# STM32F101C4T6 register map
File version: 1.0
Registers are 32-bit, access not given, reset 0x0 unless marked. A register's access mark holds for its fields unless they carry their own. Offsets are from the block's base; [hi:lo] are bit positions.

## TIM6
Base 0x40001000
Same registers: TIM7 0x40001400
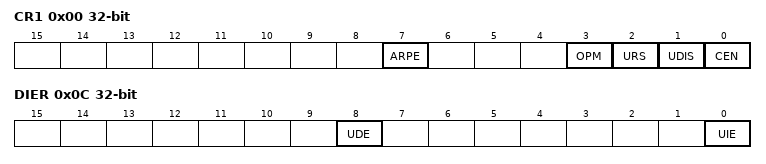
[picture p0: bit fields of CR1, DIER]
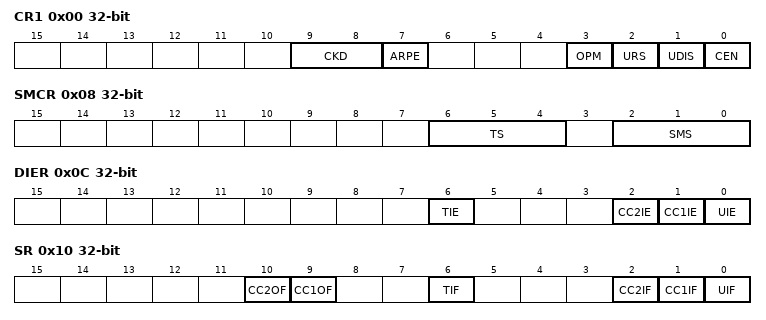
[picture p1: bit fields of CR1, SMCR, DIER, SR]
0x00 CR1
  [7] ARPE, [3] OPM, [2] URS, [1] UDIS, [0] CEN
0x04 CR2
  [6:4] MMS
0x0C DIER
  [8] UDE, [0] UIE
0x10 SR
  [0] UIF
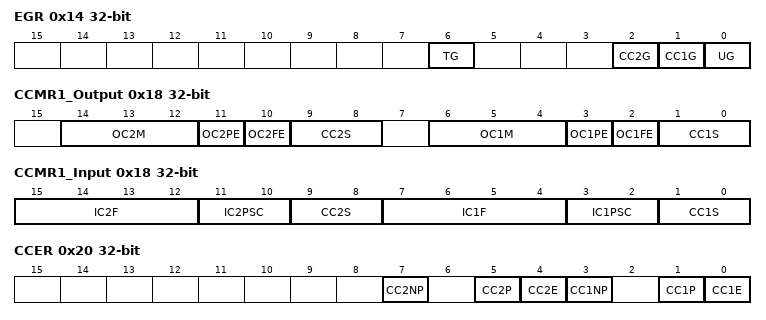
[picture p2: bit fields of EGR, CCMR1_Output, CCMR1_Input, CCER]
0x14 EGR
  [0] UG
0x24 CNT
  [15:0] CNT
0x28 PSC
  [15:0] PSC
0x2C ARR
  [15:0] ARR

## TIM12
Base 0x40001800
Same registers: TIM9 0x40014C00
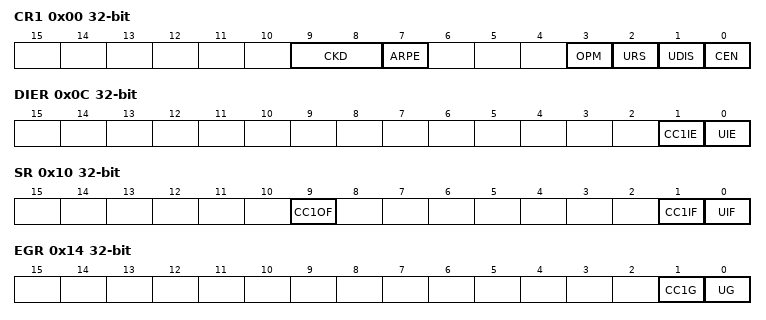
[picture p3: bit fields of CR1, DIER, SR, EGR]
0x00 CR1
  [9:8] CKD, [7] ARPE, [3] OPM, [2] URS, [1] UDIS, [0] CEN
0x08 SMCR
  [6:4] TS, [2:0] SMS
0x0C DIER
  [6] TIE, [2] CC2IE, [1] CC1IE, [0] UIE
0x10 SR
  [10] CC2OF, [9] CC1OF, [6] TIF, [2] CC2IF, [1] CC1IF, [0] UIF
0x14 EGR
  [6] TG, [2] CC2G, [1] CC1G, [0] UG
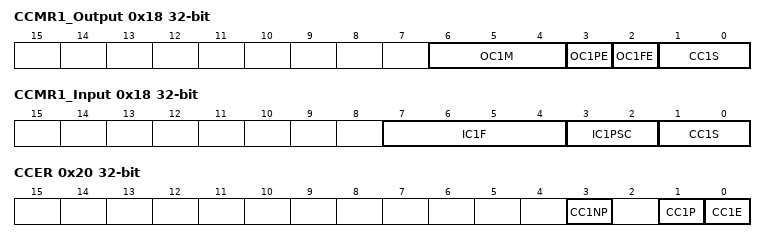
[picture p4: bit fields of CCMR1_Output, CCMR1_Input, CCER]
0x18 CCMR1_Output
  [14:12] OC2M, [11] OC2PE, [10] OC2FE, [9:8] CC2S, [6:4] OC1M, [3] OC1PE, [2] OC1FE, [1:0] CC1S
0x18 CCMR1_Input
  [15:12] IC2F, [11:10] IC2PSC, [9:8] CC2S, [7:4] IC1F, [3:2] IC1PSC, [1:0] CC1S
0x20 CCER
  [7] CC2NP, [5] CC2P, [4] CC2E, [3] CC1NP, [1] CC1P, [0] CC1E
0x24 CNT
  [15:0] CNT
0x28 PSC
  [15:0] PSC
0x2C ARR
  [15:0] ARR
0x34 CCR1
  [15:0] CCR1
0x38 CCR2
  [15:0] CCR2

## TIM13
Base 0x40001C00
Same registers: TIM14 0x40002000, TIM10 0x40015000, TIM11 0x40015400
0x00 CR1
  [9:8] CKD, [7] ARPE, [3] OPM, [2] URS, [1] UDIS, [0] CEN
0x08 SMCR
0x0C DIER
  [1] CC1IE, [0] UIE
0x10 SR
  [9] CC1OF, [1] CC1IF, [0] UIF
0x14 EGR
  [1] CC1G, [0] UG
0x18 CCMR1_Output
  [6:4] OC1M, [3] OC1PE, [2] OC1FE, [1:0] CC1S
0x18 CCMR1_Input
  [7:4] IC1F, [3:2] IC1PSC, [1:0] CC1S
0x20 CCER
  [3] CC1NP, [1] CC1P, [0] CC1E
0x24 CNT
  [15:0] CNT
0x28 PSC
  [15:0] PSC
0x2C ARR
  [15:0] ARR
0x34 CCR1
  [15:0] CCR1

## RTC
Base 0x40002800
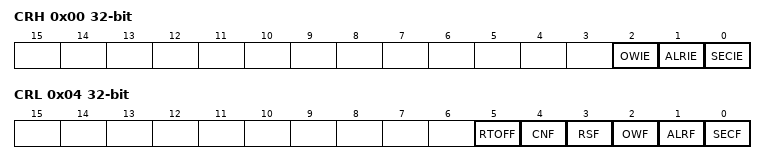
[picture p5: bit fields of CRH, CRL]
0x00 CRH
  [2] OWIE, [1] ALRIE, [0] SECIE
0x04 CRL
  [5] RTOFF, [4] CNF, [3] RSF, [2] OWF, [1] ALRF, [0] SECF
0x08 PRLH
  [3:0] PRL
0x0C PRLL
  [15:0] PRL
0x10 DIVH
  [15:0] DIV
0x14 DIVL
  [15:0] DIV
0x18 CNTH
  [15:0] CNT
0x1C CNTL
  [15:0] CNT
0x20 ALRH
  [15:0] ALR
0x24 ALRL
  [15:0] ALR

## WWDG
Base 0x40002C00
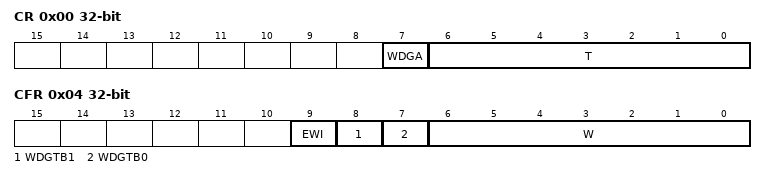
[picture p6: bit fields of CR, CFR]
0x00 CR
  [7] WDGA, [6:0] T
0x04 CFR
  [9] EWI, [8] WDGTB1, [7] WDGTB0, [6:0] W
0x08 SR
  [0] EWIF

## IWDG
Base 0x40003000
0x00 KR
  [15:0] KEY
0x04 PR
  [2:0] PR
0x08 RLR
  [11:0] RL
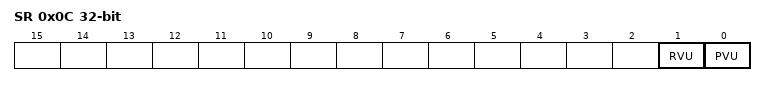
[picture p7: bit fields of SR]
0x0C SR
  [1] RVU, [0] PVU

## SPI2
Base 0x40003800
Same registers: SPI3 0x40003C00, SPI1 0x40013000
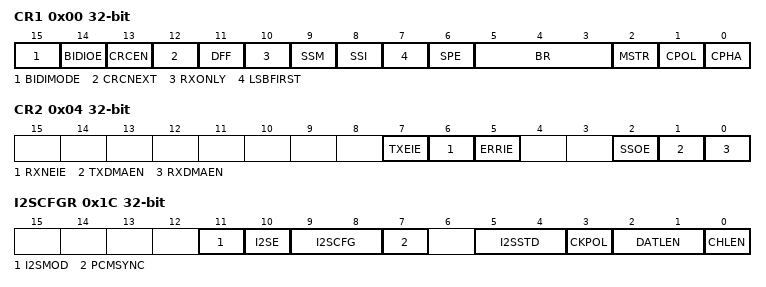
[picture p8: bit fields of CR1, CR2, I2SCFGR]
0x00 CR1
  [15] BIDIMODE, [14] BIDIOE, [13] CRCEN, [12] CRCNEXT, [11] DFF, [10] RXONLY, [9] SSM, [8] SSI, [7] LSBFIRST, [6] SPE, [5:3] BR, [2] MSTR, [1] CPOL, [0] CPHA
0x04 CR2
  [7] TXEIE, [6] RXNEIE, [5] ERRIE, [2] SSOE, [1] TXDMAEN, [0] RXDMAEN
0x08 SR
0x0C DR
  [15:0] DR
0x10 CRCPR
  [15:0] CRCPOLY
0x14 RXCRCR
  [15:0] RxCRC
0x18 TXCRCR
  [15:0] TxCRC
0x1C I2SCFGR
  [11] I2SMOD, [10] I2SE, [9:8] I2SCFG, [7] PCMSYNC, [5:4] I2SSTD, [3] CKPOL, [2:1] DATLEN, [0] CHLEN
0x20 I2SPR

## USART2
Base 0x40004400
Same registers: USART3 0x40004800, UART4 0x40004C00, UART5 0x40005000, USART1 0x40013800
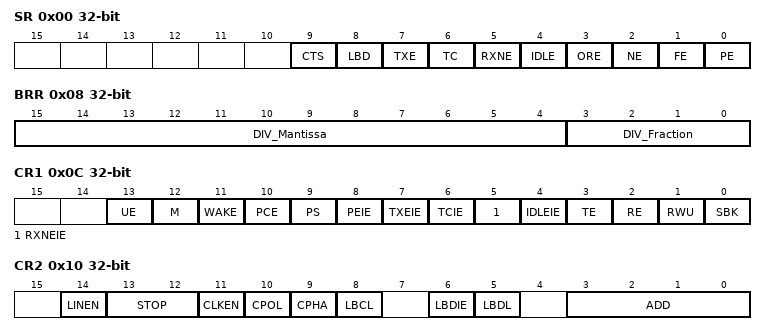
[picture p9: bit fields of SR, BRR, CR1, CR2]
0x00 SR
  [9] CTS, [8] LBD, [7] TXE, [6] TC, [5] RXNE, [4] IDLE, [3] ORE, [2] NE, [1] FE, [0] PE
0x04 DR
  [8:0] DR
0x08 BRR
  [15:4] DIV_Mantissa, [3:0] DIV_Fraction
0x0C CR1
  [13] UE, [12] M, [11] WAKE, [10] PCE, [9] PS, [8] PEIE, [7] TXEIE, [6] TCIE, [5] RXNEIE, [4] IDLEIE, [3] TE, [2] RE, [1] RWU, [0] SBK
0x10 CR2
  [14] LINEN, [13:12] STOP, [11] CLKEN, [10] CPOL, [9] CPHA, [8] LBCL, [6] LBDIE, [5] LBDL, [3:0] ADD
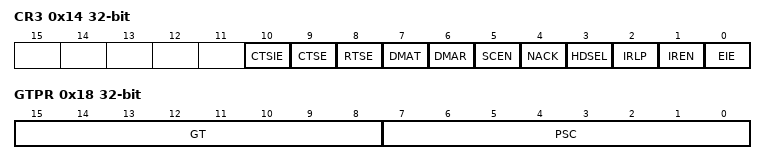
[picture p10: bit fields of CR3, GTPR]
0x14 CR3
  [10] CTSIE, [9] CTSE, [8] RTSE, [7] DMAT, [6] DMAR, [5] SCEN, [4] NACK, [3] HDSEL, [2] IRLP, [1] IREN, [0] EIE
0x18 GTPR
  [15:8] GT, [7:0] PSC

## I2C1
Base 0x40005400
Same registers: I2C2 0x40005800
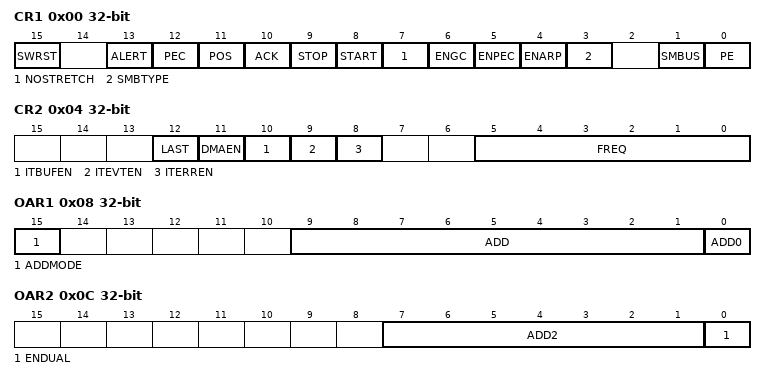
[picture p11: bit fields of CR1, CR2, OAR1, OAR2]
0x00 CR1
  [15] SWRST, [13] ALERT, [12] PEC, [11] POS, [10] ACK, [9] STOP, [8] START, [7] NOSTRETCH, [6] ENGC, [5] ENPEC, [4] ENARP, [3] SMBTYPE, [1] SMBUS, [0] PE
0x04 CR2
  [12] LAST, [11] DMAEN, [10] ITBUFEN, [9] ITEVTEN, [8] ITERREN, [5:0] FREQ
0x08 OAR1
  [15] ADDMODE, [9:1] ADD, [0] ADD0
0x0C OAR2
  [7:1] ADD2, [0] ENDUAL
0x10 DR
  [7:0] DR
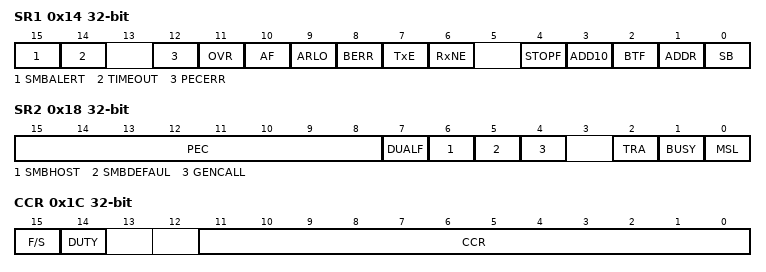
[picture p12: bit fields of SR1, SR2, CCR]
0x14 SR1
  [15] SMBALERT, [14] TIMEOUT, [12] PECERR, [11] OVR, [10] AF, [9] ARLO, [8] BERR, [7] TxE, [6] RxNE, [4] STOPF, [3] ADD10, [2] BTF, [1] ADDR, [0] SB
0x18 SR2
  [15:8] PEC, [7] DUALF, [6] SMBHOST, [5] SMBDEFAUL, [4] GENCALL, [2] TRA, [1] BUSY, [0] MSL
0x1C CCR
  [15] F/S, [14] DUTY, [11:0] CCR
0x20 TRISE
  [5:0] TRISE
